# STM32F413 register map
File version: 1.9
CPU: CM4 r0p1, little endian, MPU, FPU, 4 interrupt priority bits
Registers are 32-bit, read-write, reset 0x0 unless marked. A register's access mark holds for its fields unless they carry their own. Offsets are from the block's base; [hi:lo] are bit positions; {n}, {i} and the like mark numbered series; 'fields as' and 'values as' point back to an identical list.

## SYSCFG — System configuration controller
Base 0x40013800
0x00 MEMRMP — memory remap register
  [1:0] MEM_MODE
    0=Main Flash memory mapped at 0x0000 0000; 1=System Flash memory mapped at 0x0000 0000; 3=Embedded SRAM mapped at 0x0000 0000
0x04 PMC — peripheral mode configuration register
  [16] ADC1DC2
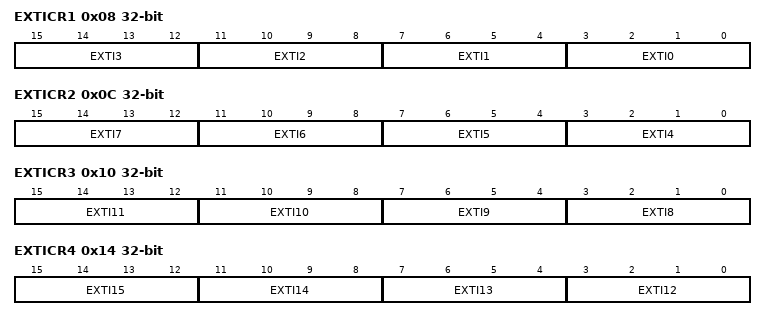
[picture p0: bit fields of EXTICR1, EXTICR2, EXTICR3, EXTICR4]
0x08 EXTICR1 — external interrupt configuration register 1
  [all] fields
    0=PA (Select PAx as the source input for the EXTIx external interrupt); 1=PB (Select PBx as the source input for the EXTIx external interrupt); 2=PC (Select PCx as the source input for the EXTIx external interrupt); 3=PD (Select PDx as the source input for the EXTIx external interrupt); 4=PE (Select PEx as the source input for the EXTIx external interrupt); 5=PF (Select PFx as the source input for the EXTIx external interrupt); 6=PG (Select PGx as the source input for the EXTIx external interrupt)
  [4n+3:4n] EXTI{n} (n=0..3) — EXTI x configuration (x = 0 to 3)
0x0C EXTICR2 — external interrupt configuration register 2
  [all] fields
    values as the fields of EXTICR1
  [4n-13:4n-16] EXTI{n} (n=4..7) — EXTI x configuration (x = 4 to 7)
0x10 EXTICR3 — external interrupt configuration register 3
  [all] fields
    values as the fields of EXTICR1
  [15:12] EXTI11 — EXTI x configuration (x = 8 to 11)
  [11:8] EXTI10
  [7:4] EXTI9 — EXTI x configuration (x = 8 to 11)
  [3:0] EXTI8 — EXTI x configuration (x = 8 to 11)
0x14 EXTICR4 — external interrupt configuration register 4
  [all] fields
    values as the fields of EXTICR1
  [4n-45:4n-48] EXTI{n} (n=12..15) — EXTI x configuration (x = 12 to 15)
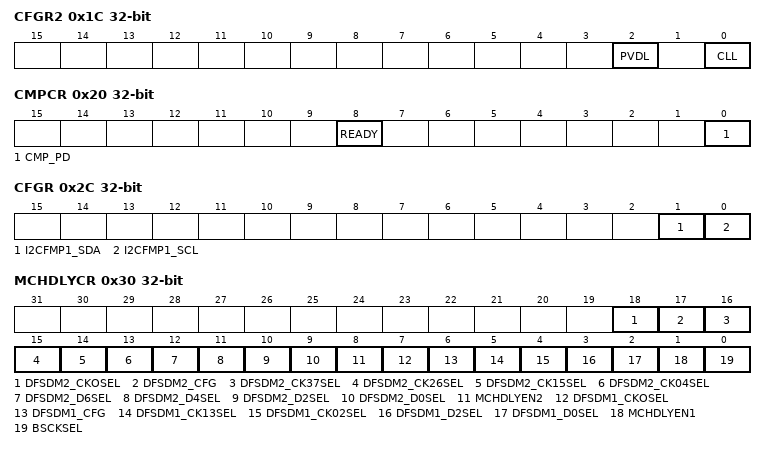
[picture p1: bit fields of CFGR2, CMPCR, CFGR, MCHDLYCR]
0x1C CFGR2 — ADC Common status register
  [2] PVDL — PVD lock
    0=NotConnected (PVD interrupt not connected to TIM1/8 Break input. PVDE and PVDS[2:0] can be read and modified); 1=Connected (PVD interrupt connected to TIM1/8 Break input. PVDE and PVDS[2:0] are read-only)
  [0] CLL — core lockup lock
    0=NotConnected (Cortex-M4 LOCKUP output not connected to TIM1/8 Break input); 1=Connected (Cortex-M4 LOCKUP output connected to TIM1/8 Break input)
0x20 CMPCR ro — Compensation cell control register
  [8] READY
    0=NotReady (I/O compensation cell not ready); 1=Ready (I/O compensation cell ready)
  [0] CMP_PD rw — Compensation cell power-down
    0=PowerDown (I/O compensation cell power-down mode); 1=Enabled (I/O compensation cell enabled)
0x2C CFGR — Configuration register
  [1] I2CFMP1_SDA — I2C4SDA
    0=Clear; 1=Forced (forces FM+ drive capability on I2CFMP1_SDA pin)
  [0] I2CFMP1_SCL — I2C4SCL
    0=Clear; 1=Forced (forces FM+ drive capability on I2CFMP1_SCL pin)
0x30 MCHDLYCR — DFSDM Multi-channel delay control register
  [18] DFSDM2_CKOSEL — Source selection for DFSDM2_CKOUT
  [17] DFSDM2_CFG — CkIn source selection for DFSDM2
  [16] DFSDM2_CK37SEL — Distribution of the DFSDM2 bitstream clock gated by TIM3 OC1
    0=CkIn3 (The gated clock is distributed to CkIn3 (DM3 = 0)); 1=CkIn7 (The gated clock is distributed to CkIn7 (DM3 = 1))
  [15] DFSDM2_CK26SEL — Distribution of the DFSDM2 bitstream clock gated by TIM3 OC2
    0=CkIn2 (The gated clock is distributed to CkIn2 (DM4 = 0)); 1=CkIn6 (The gated clock is distributed to CkIn6 (DM4 = 1))
  [14] DFSDM2_CK15SEL — Distribution of the DFSDM2 bitstream clock gated by TIM3 OC3
    0=CkIn1 (The gated clock is distributed to CkIn1 (DM5 = 0)); 1=CkIn5 (The gated clock is distributed to CkIn5 (DM5 = 1))
  [13] DFSDM2_CK04SEL — Distribution of the DFSDM2 bitstream clock gated by TIM3 OC4
    0=CkIn0 (The gated clock is distributed to CkIn0 (DM6 = 0)); 1=CkIn4 (The gated clock is distributed to CkIn4 (DM6 = 1))
  [12] DFSDM2_D6SEL — Source selection for DatIn6 of DFSDM2
  [11] DFSDM2_D4SEL — Source selection for DatIn4 of DFSDM2
  [10] DFSDM2_D2SEL — Source selection for DatIn2 of DFSDM2
  [9] DFSDM2_D0SEL — Source selection for DatIn0 of DFSDM2
  [8] MCHDLYEN2 — MCHDLY clock enable for DFSDM2
    0=Disabled (Delay clock for DFSDM2 is disabled (G[6:3] = 0)); 1=Enabled (Delay clock for DFSDM2 is enabled (G[6:3] = 1))
  [7] DFSDM1_CKOSEL — Source selection for DFSDM1_CKOUT
  [6] DFSDM1_CFG — CkIn source selection for DFSDM1
  [5] DFSDM1_CK13SEL — Distribution of the DFSDM1 bitstream clock gated by TIM4 OC1
    0=CkIn1 (The gated clock is distributed to CkIn1 (DM1 = 0)); 1=CkIn3 (The gated clock is distributed to CkIn3 (DM1 = 1))
  [4] DFSDM1_CK02SEL — Distribution of the DFSDM1 bitstream clock gated by TIM4 OC2
    0=CkIn0 (The gated clock is distributed to CkIn0 (DM2 = 0)); 1=CkIn2 (The gated clock is distributed to CkIn2 (DM2 = 1))
  [3] DFSDM1_D2SEL — Source selection for DatIn2 of DFSDM1
  [2] DFSDM1_D0SEL — Source selection for DatIn0 of DFSDM1
  [1] MCHDLYEN1 — MCHDLY clock enable for DFSDM1
    0=Disabled (Delay clock for DFSDM1 is disabled (G[2:1] = 0)); 1=Enabled (Delay clock for DFSDM1 is enabled (G[2:1] = 1))
  [0] BSCKSEL — Bitstream clock source selection
